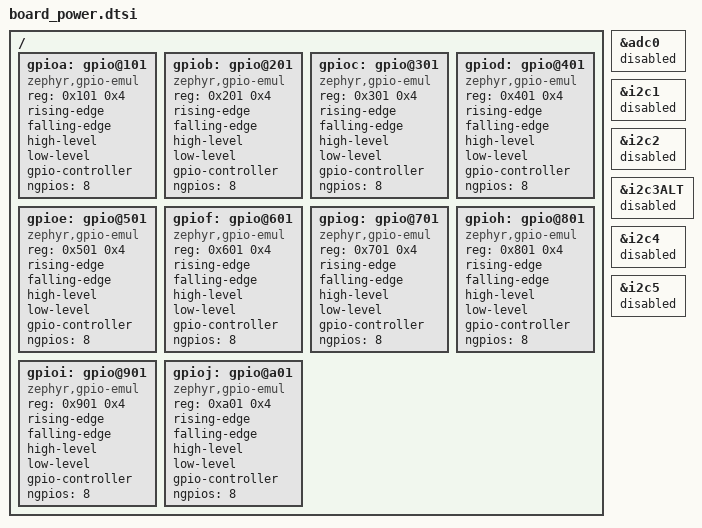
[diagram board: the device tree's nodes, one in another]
/* Copyright 2022 The ChromiumOS Authors
 * Use of this source code is governed by a BSD-style license that can be
 * found in the LICENSE file.
 */

#include <dt-bindings/gpio_defines.h>
// #include "../../../../program/brox/generated.dtsi"
// #include "../../../../program/brox/gpio.dtsi"
// #include "../../../../program/brox/power_signals.dtsi"


/ {
	/delete-node/ named-adc-channels;
	/delete-node/ named-i2c-channels;

	/* Instantiate GPIO emulators with nodelabels matching the ITE EC */
	gpioa: gpio@101 {
		status = "okay";
		compatible = "zephyr,gpio-emul";
		reg = <0x101 0x4>;
		rising-edge;
		falling-edge;
		high-level;
		low-level;
		gpio-controller;
		#gpio-cells = <2>;
		ngpios = <8>;
	};
	gpiob: gpio@201 {
		status = "okay";
		compatible = "zephyr,gpio-emul";
		reg = <0x201 0x4>;
		rising-edge;
		falling-edge;
		high-level;
		low-level;
		gpio-controller;
		#gpio-cells = <2>;
		ngpios = <8>;
	};
	gpioc: gpio@301 {
		status = "okay";
		compatible = "zephyr,gpio-emul";
		reg = <0x301 0x4>;
		rising-edge;
		falling-edge;
		high-level;
		low-level;
		gpio-controller;
		#gpio-cells = <2>;
		ngpios = <8>;
	};
	gpiod: gpio@401 {
		status = "okay";
		compatible = "zephyr,gpio-emul";
		reg = <0x401 0x4>;
		rising-edge;
		falling-edge;
		high-level;
		low-level;
		gpio-controller;
		#gpio-cells = <2>;
		ngpios = <8>;
	};
	gpioe: gpio@501 {
		status = "okay";
		compatible = "zephyr,gpio-emul";
		reg = <0x501 0x4>;
		rising-edge;
		falling-edge;
		high-level;
		low-level;
		gpio-controller;
		#gpio-cells = <2>;
		ngpios = <8>;
	};
	gpiof: gpio@601 {
		status = "okay";
		compatible = "zephyr,gpio-emul";
		reg = <0x601 0x4>;
		rising-edge;
		falling-edge;
		high-level;
		low-level;
		gpio-controller;
		#gpio-cells = <2>;
		ngpios = <8>;
	};
	gpiog: gpio@701 {
		status = "okay";
		compatible = "zephyr,gpio-emul";
		reg = <0x701 0x4>;
		rising-edge;
		falling-edge;
		high-level;
		low-level;
		gpio-controller;
		#gpio-cells = <2>;
		ngpios = <8>;
	};
	gpioh: gpio@801 {
		status = "okay";
		compatible = "zephyr,gpio-emul";
		reg = <0x801 0x4>;
		rising-edge;
		falling-edge;
		high-level;
		low-level;
		gpio-controller;
		#gpio-cells = <2>;
		ngpios = <8>;
	};
	gpioi: gpio@901 {
		status = "okay";
		compatible = "zephyr,gpio-emul";
		reg = <0x901 0x4>;
		rising-edge;
		falling-edge;
		high-level;
		low-level;
		gpio-controller;
		#gpio-cells = <2>;
		ngpios = <8>;
	};
	gpioj: gpio@a01 {
		status = "okay";
		compatible = "zephyr,gpio-emul";
		reg = <0xa01 0x4>;
		rising-edge;
		falling-edge;
		high-level;
		low-level;
		gpio-controller;
		#gpio-cells = <2>;
		ngpios = <8>;
	};

};

&adc0 {
	status = "disabled";
};

&i2c1 {
	status = "disabled";
};

&i2c2 {
	status = "disabled";
};

&i2c3ALT {
	status = "disabled";
};

&i2c4 {
	status = "disabled";
};

&i2c5 {
	status = "disabled";
};
